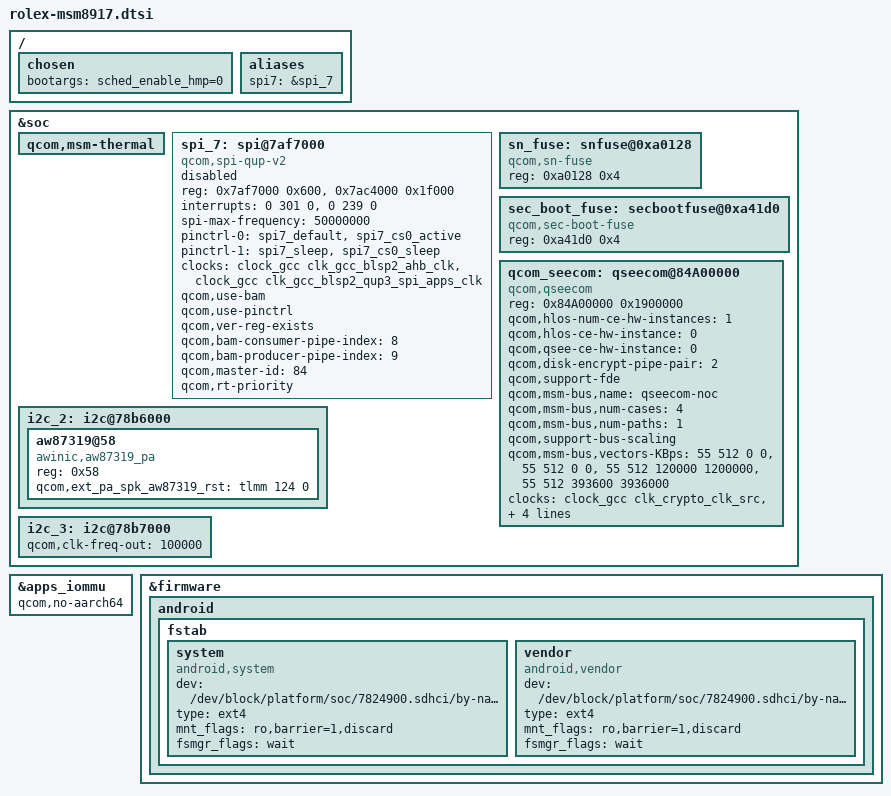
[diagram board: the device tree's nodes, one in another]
/ {
     chosen {
		bootargs = "sched_enable_hmp=0";
	};

      aliases {
                spi7 = &spi_7;
      };
};
#include "rolex-reserved-memory.dtsi"
&soc {
	qcom,msm-thermal {
		/delete-property/ qcom,therm-reset-temp;
	};

	spi_7: spi@7af7000 { /* BLSP1 QUP3 */
		compatible = "qcom,spi-qup-v2";
		#address-cells = <1>;
		#size-cells = <0>;
		reg-names = "spi_physical", "spi_bam_physical";
		reg = <0x7af7000 0x600>,
			<0x7ac4000 0x1f000>;
		interrupt-names = "spi_irq", "spi_bam_irq";
		interrupts = <0 301 0>, <0 239 0>;
		spi-max-frequency = <50000000>;
		pinctrl-names = "spi_default", "spi_sleep";
		pinctrl-0 = <&spi7_default &spi7_cs0_active>;
		pinctrl-1 = <&spi7_sleep &spi7_cs0_sleep>;
		clocks = <&clock_gcc clk_gcc_blsp2_ahb_clk>,
			<&clock_gcc clk_gcc_blsp2_qup3_spi_apps_clk>;
		clock-names = "iface_clk", "core_clk";
		qcom,use-bam;
		qcom,use-pinctrl;
		qcom,ver-reg-exists;
		qcom,bam-consumer-pipe-index = <8>;
		qcom,bam-producer-pipe-index = <9>;
		qcom,master-id = <84>;
		qcom,rt-priority;
		status = "disabled";
	};
	
	sn_fuse: snfuse@0xa0128 {
		compatible = "qcom,sn-fuse";
		reg = <0xa0128 0x4>;
		reg-names = "sn-base";
	};

	sec_boot_fuse: secbootfuse@0xa41d0 {
		compatible = "qcom,sec-boot-fuse";
		reg = <0xa41d0 0x4>;
		reg-names = "sec-boot-base";
	};

	/delete-node/ qseecom@85b00000;

	qcom_seecom: qseecom@84A00000 {
		compatible = "qcom,qseecom";
		reg = <0x84A00000 0x1900000>;
		reg-names = "secapp-region";
		qcom,hlos-num-ce-hw-instances = <1>;
		qcom,hlos-ce-hw-instance = <0>;
		qcom,qsee-ce-hw-instance = <0>;
		qcom,disk-encrypt-pipe-pair = <2>;
		qcom,support-fde;
		qcom,msm-bus,name = "qseecom-noc";
		qcom,msm-bus,num-cases = <4>;
		qcom,msm-bus,num-paths = <1>;
		qcom,support-bus-scaling;
		qcom,msm-bus,vectors-KBps =
			<55 512 0 0>,
			<55 512 0 0>,
			<55 512 120000 1200000>,
			<55 512 393600 3936000>;
		clocks = <&clock_gcc clk_crypto_clk_src>,
			 <&clock_gcc clk_gcc_crypto_clk>,
			 <&clock_gcc clk_gcc_crypto_ahb_clk>,
			 <&clock_gcc clk_gcc_crypto_axi_clk>;
		clock-names = "core_clk_src", "core_clk",
				"iface_clk", "bus_clk";
		qcom,ce-opp-freq = <100000000>;
	};
};
&soc {
       i2c_2: i2c@78b6000 { /* BLSP1 QUP2 */
        aw87319@58{ /*AW87319 PA*/
			compatible = "awinic,aw87319_pa";
			reg = <0x58>;
			qcom,ext_pa_spk_aw87319_rst = <&tlmm 124 0>;
		 };
	};

	i2c_3: i2c@78b7000 { /* BLSP1 QUP3 */
	        qcom,clk-freq-out = <100000>;
	};
};

&apps_iommu {
	qcom,no-aarch64;
};

&firmware {
	android {
           /delete-node/ vbmeta;
		fstab {
			system {
				compatible = "android,system";
				dev = "/dev/block/platform/soc/7824900.sdhci/by-name/system";
				type = "ext4";
				mnt_flags = "ro,barrier=1,discard";
				fsmgr_flags = "wait";
				status = "ok";
			};
                        vendor {
				compatible = "android,vendor";
				dev = "/dev/block/platform/soc/7824900.sdhci/by-name/cust";
				type = "ext4";
				mnt_flags = "ro,barrier=1,discard";
				fsmgr_flags = "wait";
				status = "ok";
			};
		};
	};
};
#include "rolex-cpu.dtsi"
